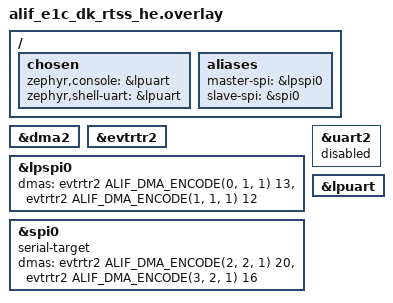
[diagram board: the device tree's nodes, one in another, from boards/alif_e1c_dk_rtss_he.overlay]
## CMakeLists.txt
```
# Copyright (C) 2024 Alif Semiconductor - All Rights Reserved.
# Use, distribution and modification of this code is permitted under the
# terms stated in the Alif Semiconductor Software License Agreement
#
# You should have received a copy of the Alif Semiconductor Software
# License Agreement with this file. If not, please write to:
# contact@alifsemi.com, or visit: https://alifsemi.com/license

cmake_minimum_required(VERSION 3.20.0)
find_package(Zephyr REQUIRED HINTS $ENV{ZEPHYR_BASE})
project(spi_dw)

FILE(GLOB app_sources src/*.c)
target_sources(app PRIVATE ${app_sources})
```

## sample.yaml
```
sample:
  name: SPI Designware Driver Sample
tests:
  sample.drivers.spi.dw:
    tags: drivers spi gpio
    platform_allow: ensemble
    depends_on: gpio
```

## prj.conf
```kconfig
# Copyright (C) 2024 Alif Semiconductor - All Rights Reserved.
# Use, distribution and modification of this code is permitted under the
# terms stated in the Alif Semiconductor Software License Agreement
#
# You should have received a copy of the Alif Semiconductor Software
# License Agreement with this file. If not, please write to:
# contact@alifsemi.com, or visit: https://alifsemi.com/license

CONFIG_STDOUT_CONSOLE=y
CONFIG_SPI=y
CONFIG_SPI_DW=y
CONFIG_SPI_SLAVE=y
CONFIG_SPI_LOG_LEVEL_INF=n
CONFIG_SPI_LOG_LEVEL_DBG=n
CONFIG_LOG=n
CONFIG_DMA=y
CONFIG_DMA_PL330=y
CONFIG_SPI_DW_USE_DMA=y
CONFIG_PRINTK=y
CONFIG_DMA_LOG_LEVEL_INF=n
```

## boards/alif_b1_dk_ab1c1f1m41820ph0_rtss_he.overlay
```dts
/* Copyright (C) 2025 Alif Semiconductor - All Rights Reserved.
 * Use, distribution and modification of this code is permitted under the
 * terms stated in the Alif Semiconductor Software License Agreement
 *
 * You should have received a copy of the Alif Semiconductor Software
 * License Agreement with this file. If not, please write to:
 * contact@alifsemi.com, or visit: https://alifsemi.com/license
 *
 */


/* For SPI master SS(slave select) as:
 * - H/W controlled (default):
 *   - use SS pinmux as H/W
 *     - example for SPI1 as master "PIN_P14_7__SPI1_SS0_C"
 *  "OR"
 * - S/W controlled using gpio:
 *   - use SS pinmux as gpio
 *     - example for SPI1 as master "PIN_P14_7__GPIO"
 *   - define cs-gpios property
 *     - example for SPI1 as master
 *        cs-gpios = <&gpio14 7 GPIO_ACTIVE_LOW>;
 */

 /* default SPI master SS(slave select) is H/W controlled,
  * enable this to use as S/W controlled using gpio.
  */
#define SPI_MASTER_SS_SW_CONTROLLED_GPIO   0

/* setting LPSPI0 as master and SPI1 instance as slave. */
/ {
	aliases {
		master-spi = &lpspi0;
		slave-spi = &spi1;
	};
};

&dma2 {
	status = "okay";
};

&lpspi0 { /* lpspi0 */
	status = "okay";

	dmas = <&dma2 0 13>, <&dma2 1 12>;
	dma-names = "txdma", "rxdma";

#if SPI_MASTER_SS_SW_CONTROLLED_GPIO
	cs-gpios = <&gpio2 0 GPIO_ACTIVE_LOW>;
	/* as we are testing Loopback on the same board,
	 * make sure master interrupt priority is
	 * higher than slave interrupt priority.
	 */
	interrupts = <46 0>;
#endif /* SPI_MASTER_SS_SW_CONTROLLED_GPIO */
};

#if SPI_MASTER_SS_SW_CONTROLLED_GPIO
/* use SPI master SS pinmux as gpio. */
&pinctrl_lpspi0 {
	group0 {
		pinmux = < PIN_P1_3__LPSPI_MISO_A >,
			 < PIN_P1_4__LPSPI_MOSI_A >,
			 < PIN_P1_5__LPSPI_SCLK_A >,
			 < PIN_P2_0__GPIO >;
		read-enable = < 0x1 >;
	};
};

&gpio2 {
	status = "okay";
};
#endif /* SPI_MASTER_SS_SW_CONTROLLED_GPIO */

&spi1 { /* spi1 */
	status = "okay";
	serial-target;

	dmas = <&dma2 2 21>, <&dma2 3 17>;
	dma-names = "txdma", "rxdma";

#if SPI_MASTER_SS_SW_CONTROLLED_GPIO
	interrupts = <138 1>;
#endif
};
```

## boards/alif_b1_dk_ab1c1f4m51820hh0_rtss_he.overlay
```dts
/* Copyright (C) 2025 Alif Semiconductor - All Rights Reserved.
 * Use, distribution and modification of this code is permitted under the
 * terms stated in the Alif Semiconductor Software License Agreement
 *
 * You should have received a copy of the Alif Semiconductor Software
 * License Agreement with this file. If not, please write to:
 * contact@alifsemi.com, or visit: https://alifsemi.com/license
 *
 */


/* For SPI master SS(slave select) as:
 * - H/W controlled (default):
 *   - use SS pinmux as H/W
 *     - example for SPI1 as master "PIN_P14_7__SPI1_SS0_C"
 *  "OR"
 * - S/W controlled using gpio:
 *   - use SS pinmux as gpio
 *     - example for SPI1 as master "PIN_P14_7__GPIO"
 *   - define cs-gpios property
 *     - example for SPI1 as master
 *        cs-gpios = <&gpio14 7 GPIO_ACTIVE_LOW>;
 */

 /* default SPI master SS(slave select) is H/W controlled,
  * enable this to use as S/W controlled using gpio.
  */
#define SPI_MASTER_SS_SW_CONTROLLED_GPIO   0

/* Enable to use Event Router driver instead of manual configuration
 * When enabled:
 * - DMA routing goes through event router driver
 * - Manual event router configuration in main.c is disabled
 * When disabled:
 * - Direct DMA approach with manual event router programming
 */
#define USE_EVENT_ROUTER_DRIVER   1

/* setting LPSPI0 as master and SPI1 instance as slave. */
/ {
	aliases {
		master-spi = &lpspi0;
		slave-spi = &spi1;
	};
};

&dma2 {
	status = "okay";
};

#if USE_EVENT_ROUTER_DRIVER
/* Event Router driver approach: route through event router */
#include <zephyr/dt-bindings/dma/alif_dma_event_router.h>

&evtrtr2 {
	status = "okay";
};

&lpspi0 { /* lpspi0 */
	status = "okay";
	/*
	 * Cell 0: ALIF_DMA_ENCODE(channel, dma_group, handshake)
	 *   - channel: Physical DMA channel (0 for TX, 1 for RX)
	 *   - dma_group: Input source selection (2) - selects which peripheral input
	 *   - handshake: Enable hardware handshaking (1 for SPI)
	 * Cell 1: Peripheral request number (13 for TX, 12 for RX)
	 */
	dmas = <&evtrtr2 ALIF_DMA_ENCODE(0, 1, 1) 13>,
	       <&evtrtr2 ALIF_DMA_ENCODE(1, 1, 1) 12>;
	dma-names = "txdma", "rxdma";

#if SPI_MASTER_SS_SW_CONTROLLED_GPIO
	cs-gpios = <&gpio2 0 GPIO_ACTIVE_LOW>;
	/* as we are testing Loopback on the same board,
	 * make sure master interrupt priority is
	 * higher than slave interrupt priority.
	 */
	interrupts = <46 0>;
#endif /* SPI_MASTER_SS_SW_CONTROLLED_GPIO */
};

&spi1 { /* spi1 */
	status = "okay";
	serial-target;
	/*
	 * Cell 0: ALIF_DMA_ENCODE(channel, dma_group, handshake)
	 *   - channel: Physical DMA channel (2 for TX, 3 for RX)
	 *   - dma_group: Input source selection (2) - selects which peripheral input
	 *   - handshake: Enable hardware handshaking (1 for SPI)
	 * Cell 1: Peripheral request number (21 for TX, 17 for RX)
	 */
	dmas = <&evtrtr2 ALIF_DMA_ENCODE(2, 2, 1) 21>,
	       <&evtrtr2 ALIF_DMA_ENCODE(3, 2, 1) 17>;
	dma-names = "txdma", "rxdma";

#if SPI_MASTER_SS_SW_CONTROLLED_GPIO
	interrupts = <138 1>;
#endif
};

#else
/* Direct DMA approach: manual event router configuration in main.c */

&lpspi0 { /* lpspi0 */
	status = "okay";
	/* Direct PL330 DMA specifier format:
	 * Cell 0: PL330 physical channel (0 for TX, 1 for RX)
	 * Cell 1: PL330 peripheral request (13 for TX, 12 for RX)
	 * Note: Event router is manually configured in main.c
	 */
	dmas = <&dma2 0 13>, <&dma2 1 12>;
	dma-names = "txdma", "rxdma";

#if SPI_MASTER_SS_SW_CONTROLLED_GPIO
	cs-gpios = <&gpio2 0 GPIO_ACTIVE_LOW>;
	/* as we are testing Loopback on the same board,
	 * make sure master interrupt priority is
	 * higher than slave interrupt priority.
	 */
	interrupts = <46 0>;
#endif /* SPI_MASTER_SS_SW_CONTROLLED_GPIO */
};

&spi1 { /* spi1 */
	status = "okay";
	serial-target;
	/* Direct PL330 DMA specifier format:
	 * Cell 0: PL330 physical channel (2 for TX, 3 for RX)
	 * Cell 1: PL330 peripheral request (21 for TX, 17 for RX)
	 * Note: Event router is manually configured in main.c
	 */
	dmas = <&dma2 2 21>, <&dma2 3 17>;
	dma-names = "txdma", "rxdma";

#if SPI_MASTER_SS_SW_CONTROLLED_GPIO
	interrupts = <138 1>;
#endif
};

#endif /* USE_EVENT_ROUTER_DRIVER */

#if SPI_MASTER_SS_SW_CONTROLLED_GPIO
/* use SPI master SS pinmux as gpio. */
&pinctrl_lpspi0 {
	group0 {
		pinmux = < PIN_P1_3__LPSPI_MISO_A >,
			 < PIN_P1_4__LPSPI_MOSI_A >,
			 < PIN_P1_5__LPSPI_SCLK_A >,
			 < PIN_P2_0__GPIO >;
		read-enable = < 0x1 >;
	};
};

&gpio2 {
	status = "okay";
};
#endif /* SPI_MASTER_SS_SW_CONTROLLED_GPIO */
```

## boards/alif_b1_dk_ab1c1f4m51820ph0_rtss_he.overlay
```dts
/* Copyright (C) 2025 Alif Semiconductor - All Rights Reserved.
 * Use, distribution and modification of this code is permitted under the
 * terms stated in the Alif Semiconductor Software License Agreement
 *
 * You should have received a copy of the Alif Semiconductor Software
 * License Agreement with this file. If not, please write to:
 * contact@alifsemi.com, or visit: https://alifsemi.com/license
 *
 */


/* For SPI master SS(slave select) as:
 * - H/W controlled (default):
 *   - use SS pinmux as H/W
 *     - example for SPI1 as master "PIN_P14_7__SPI1_SS0_C"
 *  "OR"
 * - S/W controlled using gpio:
 *   - use SS pinmux as gpio
 *     - example for SPI1 as master "PIN_P14_7__GPIO"
 *   - define cs-gpios property
 *     - example for SPI1 as master
 *        cs-gpios = <&gpio14 7 GPIO_ACTIVE_LOW>;
 */

 /* default SPI master SS(slave select) is H/W controlled,
  * enable this to use as S/W controlled using gpio.
  */
#define SPI_MASTER_SS_SW_CONTROLLED_GPIO   0

/* Enable to use Event Router driver instead of manual configuration
 * When enabled:
 * - DMA routing goes through event router driver
 * - Manual event router configuration in main.c is disabled
 * When disabled:
 * - Direct DMA approach with manual event router programming
 */
#define USE_EVENT_ROUTER_DRIVER   1

/* setting LPSPI0 as master and SPI1 instance as slave. */
/ {
	aliases {
		master-spi = &lpspi0;
		slave-spi = &spi1;
	};
};

&dma2 {
	status = "okay";
};

#if USE_EVENT_ROUTER_DRIVER
/* Event Router driver approach: route through event router */
#include <zephyr/dt-bindings/dma/alif_dma_event_router.h>

&evtrtr2 {
	status = "okay";
};

&lpspi0 { /* lpspi0 */
	status = "okay";
	/*
	 * Cell 0: ALIF_DMA_ENCODE(channel, dma_group, handshake)
	 *   - channel: Physical DMA channel (0 for TX, 1 for RX)
	 *   - dma_group: Input source selection (2) - selects which peripheral input
	 *   - handshake: Enable hardware handshaking (1 for SPI)
	 * Cell 1: Peripheral request number (13 for TX, 12 for RX)
	 */
	dmas = <&evtrtr2 ALIF_DMA_ENCODE(0, 1, 1) 13>,
	       <&evtrtr2 ALIF_DMA_ENCODE(1, 1, 1) 12>;
	dma-names = "txdma", "rxdma";

#if SPI_MASTER_SS_SW_CONTROLLED_GPIO
	cs-gpios = <&gpio2 0 GPIO_ACTIVE_LOW>;
	/* as we are testing Loopback on the same board,
	 * make sure master interrupt priority is
	 * higher than slave interrupt priority.
	 */
	interrupts = <46 0>;
#endif /* SPI_MASTER_SS_SW_CONTROLLED_GPIO */
};

&spi1 { /* spi1 */
	status = "okay";
	serial-target;
	/*
	 * Cell 0: ALIF_DMA_ENCODE(channel, dma_group, handshake)
	 *   - channel: Physical DMA channel (2 for TX, 3 for RX)
	 *   - dma_group: Input source selection (2) - selects which peripheral input
	 *   - handshake: Enable hardware handshaking (1 for SPI)
	 * Cell 1: Peripheral request number (21 for TX, 17 for RX)
	 */
	dmas = <&evtrtr2 ALIF_DMA_ENCODE(2, 2, 1) 21>,
	       <&evtrtr2 ALIF_DMA_ENCODE(3, 2, 1) 17>;
	dma-names = "txdma", "rxdma";

#if SPI_MASTER_SS_SW_CONTROLLED_GPIO
	interrupts = <138 1>;
#endif
};

#else
/* Direct DMA approach: manual event router configuration in main.c */

&lpspi0 { /* lpspi0 */
	status = "okay";
	/* Direct PL330 DMA specifier format:
	 * Cell 0: PL330 physical channel (0 for TX, 1 for RX)
	 * Cell 1: PL330 peripheral request (13 for TX, 12 for RX)
	 * Note: Event router is manually configured in main.c
	 */
	dmas = <&dma2 0 13>, <&dma2 1 12>;
	dma-names = "txdma", "rxdma";

#if SPI_MASTER_SS_SW_CONTROLLED_GPIO
	cs-gpios = <&gpio2 0 GPIO_ACTIVE_LOW>;
	/* as we are testing Loopback on the same board,
	 * make sure master interrupt priority is
	 * higher than slave interrupt priority.
	 */
	interrupts = <46 0>;
#endif /* SPI_MASTER_SS_SW_CONTROLLED_GPIO */
};

&spi1 { /* spi1 */
	status = "okay";
	serial-target;
	/* Direct PL330 DMA specifier format:
	 * Cell 0: PL330 physical channel (2 for TX, 3 for RX)
	 * Cell 1: PL330 peripheral request (21 for TX, 17 for RX)
	 * Note: Event router is manually configured in main.c
	 */
	dmas = <&dma2 2 21>, <&dma2 3 17>;
	dma-names = "txdma", "rxdma";

#if SPI_MASTER_SS_SW_CONTROLLED_GPIO
	interrupts = <138 1>;
#endif
};

#endif /* USE_EVENT_ROUTER_DRIVER */

#if SPI_MASTER_SS_SW_CONTROLLED_GPIO
/* use SPI master SS pinmux as gpio. */
&pinctrl_lpspi0 {
	group0 {
		pinmux = < PIN_P1_3__LPSPI_MISO_A >,
			 < PIN_P1_4__LPSPI_MOSI_A >,
			 < PIN_P1_5__LPSPI_SCLK_A >,
			 < PIN_P2_0__GPIO >;
		read-enable = < 0x1 >;
	};
};

&gpio2 {
	status = "okay";
};
#endif /* SPI_MASTER_SS_SW_CONTROLLED_GPIO */
```

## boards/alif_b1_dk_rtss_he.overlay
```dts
/* Copyright (C) 2025 Alif Semiconductor - All Rights Reserved.
* Use, distribution and modification of this code is permitted under the
* terms stated in the Alif Semiconductor Software License Agreement
*
* You should have received a copy of the Alif Semiconductor Software
* License Agreement with this file. If not, please write to:
* contact@alifsemi.com, or visit: https://alifsemi.com/license
*
*/

/* setting LPSPI0 as master and SPI0 instance as slave.
 *
 */

/* For SPI master SS(slave select) as:
 * - H/W controlled (default):
 *   - use SS pinmux as H/W
 *     - example for SPI1 as master "PIN_P14_7__SPI1_SS0_C"
 *  "OR"
 * - S/W controlled using gpio:
 *   - use SS pinmux as gpio
 *     - example for SPI1 as master "PIN_P14_7__GPIO"
 *   - define cs-gpios property
 *     - example for SPI1 as master
 *        cs-gpios = <&gpio14 7 GPIO_ACTIVE_LOW>;
 */

 /* default SPI master SS(slave select) is H/W controlled,
  * enable this to use as S/W controlled using gpio.
  */
#define SPI_MASTER_SS_SW_CONTROLLED_GPIO   0

/ {

	chosen {
		zephyr,console = &lpuart;
		zephyr,shell-uart = &lpuart;
	};
	aliases {
		master-spi = &lpspi0;
		slave-spi = &spi0;
	};
};

&dma2 {
	status = "okay";
};

&lpspi0 {
	status = "okay";

	dmas = <&dma2 0 13>, <&dma2 1 12>;
	dma-names = "txdma", "rxdma";

#if SPI_MASTER_SS_SW_CONTROLLED_GPIO
	cs-gpios = <&gpio2 0 GPIO_ACTIVE_LOW>;
	/* as we are testing Loopback on the same board,
	 * make sure master interrupt priority is
	 * higher than slave interrupt priority.
	 */
	interrupts = <46 0>;
#endif /* SPI_MASTER_SS_SW_CONTROLLED_GPIO */
};

#if SPI_MASTER_SS_SW_CONTROLLED_GPIO
/* use SPI master SS pinmux as gpio. */
&pinctrl_lpspi0 {
	group0 {
		pinmux = < PIN_P1_3__LPSPI_MISO_A >,
			 < PIN_P1_4__LPSPI_MOSI_A >,
			 < PIN_P1_5__LPSPI_SCLK_A >,
			 < PIN_P2_0__GPIO >;
		read-enable = < 0x1 >;
	};
};

&gpio2 {
	status = "okay";
};
#endif /* SPI_MASTER_SS_SW_CONTROLLED_GPIO */

&spi0 {
	status = "okay";
	serial-target;

	dmas = <&dma2 2 20>, <&dma2 3 16>;
	dma-names = "txdma", "rxdma";

#if SPI_MASTER_SS_SW_CONTROLLED_GPIO
	interrupts = <137 1>;
#endif
};

&uart2 {
	status = "disabled";
};

&lpuart {
	status = "okay";
};
```

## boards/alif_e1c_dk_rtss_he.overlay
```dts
/* Copyright (C) 2025 Alif Semiconductor - All Rights Reserved.
* Use, distribution and modification of this code is permitted under the
* terms stated in the Alif Semiconductor Software License Agreement
*
* You should have received a copy of the Alif Semiconductor Software
* License Agreement with this file. If not, please write to:
* contact@alifsemi.com, or visit: https://alifsemi.com/license
*
*/

/* setting LPSPI0 as master and SPI0 instance as slave.
*
*/

/* For SPI master SS(slave select) as:
 * - H/W controlled (default):
 *   - use SS pinmux as H/W
 *     - example for SPI1 as master "PIN_P14_7__SPI1_SS0_C"
 *  "OR"
 * - S/W controlled using gpio:
 *   - use SS pinmux as gpio
 *     - example for SPI1 as master "PIN_P14_7__GPIO"
 *   - define cs-gpios property
 *     - example for SPI1 as master
 *        cs-gpios = <&gpio14 7 GPIO_ACTIVE_LOW>;
 */

 /* default SPI master SS(slave select) is H/W controlled,
  * enable this to use as S/W controlled using gpio.
  */
#define SPI_MASTER_SS_SW_CONTROLLED_GPIO   0

/* Enable to use Event Router driver instead of manual configuration
 * When enabled:
 * - DMA routing goes through event router driver
 * - Manual event router configuration in main.c is disabled
 * When disabled:
 * - Direct DMA approach with manual event router programming
 */
#define USE_EVENT_ROUTER_DRIVER   1

/ {

	chosen {
		zephyr,console = &lpuart;
		zephyr,shell-uart = &lpuart;
	};
	aliases {
		master-spi = &lpspi0;
		slave-spi = &spi0;
	};
};

&dma2 {
	status = "okay";
};

#if USE_EVENT_ROUTER_DRIVER
/* Event Router driver approach: route through event router */
#include <zephyr/dt-bindings/dma/alif_dma_event_router.h>

&evtrtr2 {
	status = "okay";
};

&lpspi0 {
	status = "okay";
	/*
	 * Cell 0: ALIF_DMA_ENCODE(channel, dma_group, handshake)
	 *   - channel: Physical DMA channel (0 for TX, 1 for RX)
	 *   - dma_group: Input source selection (2) - selects which peripheral input
	 *   - handshake: Enable hardware handshaking (1 for SPI)
	 * Cell 1: Peripheral request number (13 for TX, 12 for RX)
	 */
	dmas = <&evtrtr2 ALIF_DMA_ENCODE(0, 1, 1) 13>,
	       <&evtrtr2 ALIF_DMA_ENCODE(1, 1, 1) 12>;
	dma-names = "txdma", "rxdma";

#if SPI_MASTER_SS_SW_CONTROLLED_GPIO
	cs-gpios = <&gpio2 0 GPIO_ACTIVE_LOW>;
	/* as we are testing Loopback on the same board,
	 * make sure master interrupt priority is
	 * higher than slave interrupt priority.
	 */
	interrupts = <46 0>;
#endif /* SPI_MASTER_SS_SW_CONTROLLED_GPIO */
};

&spi0 {
	status = "okay";
	serial-target;
	/*
	 * Cell 0: ALIF_DMA_ENCODE(channel, dma_group, handshake)
	 *   - channel: Physical DMA channel (2 for TX, 3 for RX)
	 *   - dma_group: Input source selection (2) - selects which peripheral input
	 *   - handshake: Enable hardware handshaking (1 for SPI)
	 * Cell 1: Peripheral request number (20 for TX, 16 for RX)
	 */
	dmas = <&evtrtr2 ALIF_DMA_ENCODE(2, 2, 1) 20>,
	       <&evtrtr2 ALIF_DMA_ENCODE(3, 2, 1) 16>;
	dma-names = "txdma", "rxdma";

#if SPI_MASTER_SS_SW_CONTROLLED_GPIO
	interrupts = <137 1>;
#endif
};

#else
/* Direct DMA approach: manual event router configuration in main.c */

&lpspi0 {
	status = "okay";
	/* Direct PL330 DMA specifier format:
	 * Cell 0: PL330 physical channel (0 for TX, 1 for RX)
	 * Cell 1: PL330 peripheral request (13 for TX, 12 for RX)
	 * Note: Event router is manually configured in main.c
	 */
	dmas = <&dma2 0 13>, <&dma2 1 12>;
	dma-names = "txdma", "rxdma";

#if SPI_MASTER_SS_SW_CONTROLLED_GPIO
	cs-gpios = <&gpio2 0 GPIO_ACTIVE_LOW>;
	/* as we are testing Loopback on the same board,
	 * make sure master interrupt priority is
	 * higher than slave interrupt priority.
	 */
	interrupts = <46 0>;
#endif /* SPI_MASTER_SS_SW_CONTROLLED_GPIO */
};

&spi0 {
	status = "okay";
	serial-target;
	/* Direct PL330 DMA specifier format:
	 * Cell 0: PL330 physical channel (2 for TX, 3 for RX)
	 * Cell 1: PL330 peripheral request (20 for TX, 16 for RX)
	 * Note: Event router is manually configured in main.c
	 */
	dmas = <&dma2 2 20>, <&dma2 3 16>;
	dma-names = "txdma", "rxdma";

#if SPI_MASTER_SS_SW_CONTROLLED_GPIO
	interrupts = <137 1>;
#endif
};

#endif /* USE_EVENT_ROUTER_DRIVER */

#if SPI_MASTER_SS_SW_CONTROLLED_GPIO
/* use SPI master SS pinmux as gpio. */
&pinctrl_lpspi0 {
	group0 {
		pinmux = < PIN_P1_3__LPSPI_MISO_A >,
			 < PIN_P1_4__LPSPI_MOSI_A >,
			 < PIN_P1_5__LPSPI_SCLK_A >,
			 < PIN_P2_0__GPIO >;
		read-enable = < 0x1 >;
	};
};

&gpio2 {
	status = "okay";
};
#endif /* SPI_MASTER_SS_SW_CONTROLLED_GPIO */

&uart2 {
	status = "disabled";
};

&lpuart {
	status = "okay";
};
```

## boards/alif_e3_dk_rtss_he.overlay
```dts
/* Copyright (C) 2025 Alif Semiconductor - All Rights Reserved.
 * Use, distribution and modification of this code is permitted under the
 * terms stated in the Alif Semiconductor Software License Agreement
 *
 * You should have received a copy of the Alif Semiconductor Software
 * License Agreement with this file. If not, please write to:
 * contact@alifsemi.com, or visit: https://alifsemi.com/license
 *
 */

/* setting SPI4 as master and SPI0 instance as slave.
 *
 */

/* For SPI master SS(slave select) as:
 * - H/W controlled (default):
 *   - use SS pinmux as H/W
 *     - example for SPI4 as master "PIN_P7_7__LPSPI_SS_A"
 *  "OR"
 * - S/W controlled using gpio:
 *   - use SS pinmux as gpio
 *     - example for SPI4 as master "PIN_P7_7__GPIO"
 *   - define cs-gpios property
 *     - example for SPI4 as master
 *        cs-gpios = <&gpio7 7 GPIO_ACTIVE_LOW>;
 */

/* default SPI master SS(slave select) is H/W controlled,
 * enable this to use as S/W controlled using gpio.
 */
#define SPI_MASTER_SS_SW_CONTROLLED_GPIO   0

/* Enable to use Event Router driver instead of manual configuration
 * When enabled:
 * - DMA routing goes through event router driver
 * - Manual event router configuration in main.c is disabled
 * When disabled:
 * - Direct DMA approach with manual event router programming
 */
#define USE_EVENT_ROUTER_DRIVER   1

/ {
	aliases {
		master-spi = &spi4;
		slave-spi = &spi0;
	};
};

&dma2 {
	status = "okay";
};

&dma0 {
	status = "okay";
};

#if USE_EVENT_ROUTER_DRIVER
/* Event Router driver approach: route through event router */
#include <zephyr/dt-bindings/dma/alif_dma_event_router.h>

&evtrtr2 {
	status = "okay";
};

&evtrtr0 {
	status = "okay";
};

&spi4 {
	status = "okay";
	/*
	 * Cell 0: ALIF_DMA_ENCODE(channel, dma_group, handshake)
	 *   - channel: Physical DMA channel (0 for TX, 1 for RX)
	 *   - dma_group: Input source selection (0) - selects which peripheral input
	 *   - handshake: Enable hardware handshaking (1 for SPI)
	 * Cell 1: Peripheral request number (13 for TX, 12 for RX)
	 */
	dmas = <&evtrtr2 ALIF_DMA_ENCODE(0, 0, 1) 13>,
	       <&evtrtr2 ALIF_DMA_ENCODE(1, 0, 1) 12>;
/* If user wants to use dma0 for master spi(spi4) with event router:
 * dmas = <&evtrtr0 ALIF_DMA_ENCODE(0, 2, 1) 25>,
 *        <&evtrtr0 ALIF_DMA_ENCODE(1, 2, 1) 24>;
 */
	dma-names = "txdma", "rxdma";

#if SPI_MASTER_SS_SW_CONTROLLED_GPIO
	cs-gpios = <&gpio7 7 GPIO_ACTIVE_LOW>;
	/* as we are testing Loopback on the same board,
	 * make sure master interrupt priority is
	 * higher than slave interrupt priority.
	 */
	interrupts = <46 0>;
#endif /* SPI_MASTER_SS_SW_CONTROLLED_GPIO */
};

&spi0 {
	status = "okay";
	serial-target;
	/*
	 * Cell 0: ALIF_DMA_ENCODE(channel, dma_group, handshake)
	 *   - channel: Physical DMA channel (2 for TX, 3 for RX)
	 *   - dma_group: Input source selection (2) - selects which peripheral input
	 *   - handshake: Enable hardware handshaking (1 for SPI)
	 * Cell 1: Peripheral request number (20 for TX, 16 for RX)
	 */
	dmas = <&evtrtr0 ALIF_DMA_ENCODE(2, 2, 1) 20>,
	       <&evtrtr0 ALIF_DMA_ENCODE(3, 2, 1) 16>;
	dma-names = "txdma", "rxdma";

#if SPI_MASTER_SS_SW_CONTROLLED_GPIO
	interrupts = <137 1>;
#endif
};

#else
/* Direct DMA approach: manual event router configuration in main.c */

&spi4 {
	status = "okay";
	/* Direct PL330 DMA specifier format:
	 * Cell 0: PL330 physical channel (0 for TX, 1 for RX)
	 * Cell 1: PL330 peripheral request (13 for TX, 12 for RX)
	 * Note: Event router is manually configured in main.c
	 */
	dmas = <&dma2 0 13>, <&dma2 1 12>;
/* If user want to use dma0 for master spi(spi4),
 * add below dmas property:
 * dmas = <&dma0 0 25>, <&dma0 1 24>;
 */
	dma-names = "txdma", "rxdma";

#if SPI_MASTER_SS_SW_CONTROLLED_GPIO
	cs-gpios = <&gpio7 7 GPIO_ACTIVE_LOW>;
	/* as we are testing Loopback on the same board,
	 * make sure master interrupt priority is
	 * higher than slave interrupt priority.
	 */
	interrupts = <46 0>;
#endif /* SPI_MASTER_SS_SW_CONTROLLED_GPIO */
};

&spi0 {
	status = "okay";
	serial-target;
	/* Direct PL330:
	 * Cell 0: PL330 physical channel (2 for TX, 3 for RX)
	 * Cell 1: PL330 peripheral request (20 for TX, 16 for RX)
	 * Note: Event router is manually configured in main.c
	 */
	dmas = <&dma0 2 20>, <&dma0 3 16>;
	dma-names = "txdma", "rxdma";

#if SPI_MASTER_SS_SW_CONTROLLED_GPIO
	interrupts = <137 1>;
#endif
};

#endif /* USE_EVENT_ROUTER_DRIVER */

#if SPI_MASTER_SS_SW_CONTROLLED_GPIO
/* use SPI master SS pinmux as gpio. */
&pinctrl_lpspi {
	group0 {
		pinmux = < PIN_P7_4__LPSPI_MISO_A >,
			 < PIN_P7_5__LPSPI_MOSI_A >,
			 < PIN_P7_6__LPSPI_SCLK_A >,
			 < PIN_P7_7__GPIO >;
		read-enable = < 0x1 >;
	};
};

&gpio7 {
	status = "okay";
};
#endif /* SPI_MASTER_SS_SW_CONTROLLED_GPIO */
```

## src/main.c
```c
/* Copyright (C) 2025 Alif Semiconductor - All Rights Reserved.
 * Use, distribution and modification of this code is permitted under the
 * terms stated in the Alif Semiconductor Software License Agreement
 *
 * You should have received a copy of the Alif Semiconductor Software
 * License Agreement with this file. If not, please write to:
 * contact@alifsemi.com, or visit: https://alifsemi.com/license
 *
 */

#include <zephyr/logging/log.h>
LOG_MODULE_REGISTER(app, LOG_LEVEL_INF);

#include <zephyr/kernel.h>
#include <zephyr/device.h>
#include <zephyr/devicetree.h>
#include <string.h>
#include <zephyr/drivers/spi.h>
#include <zephyr/dt-bindings/dma/alif_dma_event_router.h>
#include <soc_common.h>

#define Mhz		1000000
#define Khz		1000

/* master_spi and slave_spi aliases are defined in
 * overlay files to use different SPI instance if needed.
 */

#define SPIDW_NODE	DT_ALIAS(master_spi)

#define S_SPIDW_NODE	DT_ALIAS(slave_spi)

/* size of stack area used by each thread */
#define STACKSIZE 1024

/* default SPI master SS(slave select) is H/W controlled,
 * enable this to use as S/W controlled using gpio.
 */
#define SPI_MASTER_SS_SW_CONTROLLED_GPIO   0


/* scheduling priority used by each thread,
 * as we are testing Loopback on the same board,
 * make sure master priority is higher than slave priority.
 */
#define MASTER_PRIORITY 6
#define SLAVE_PRIORITY  7

/* delay between greetings (in ms) */
#define SLEEPTIME 1000

K_THREAD_STACK_DEFINE(MasterT_stack, STACKSIZE);
static struct k_thread MasterT_data;

K_THREAD_STACK_DEFINE(SlaveT_stack, STACKSIZE);
static struct k_thread SlaveT_data;

/* Master and Slave buffer size */
#define BUFF_SIZE  200

/* Master and Slave buffer word size */
#define SPI_WORD_SIZE 8

/* Master and Slave buffer frequency */
#define SPI_FREQUENCY (1 * Mhz)

/* Master and Slave buffer transfers */
#define SPI_NUM_TRANSFERS  10

#define SPI_BUF_BYTES ROUND_UP(BUFF_SIZE * sizeof(uint32_t), CONFIG_DCACHE_LINE_SIZE)
#define SPI_BUF_WORDS (SPI_BUF_BYTES / sizeof(uint32_t))

/* Master and Slave buffers */
static __aligned(CONFIG_DCACHE_LINE_SIZE) uint32_t master_txdata[SPI_BUF_WORDS];
static __aligned(CONFIG_DCACHE_LINE_SIZE) uint32_t master_rxdata[SPI_BUF_WORDS];
static __aligned(CONFIG_DCACHE_LINE_SIZE) uint32_t slave_txdata[SPI_BUF_WORDS];
static __aligned(CONFIG_DCACHE_LINE_SIZE) uint32_t slave_rxdata[SPI_BUF_WORDS];

/*
 * Send/Receive data through slave spi
 */
int slave_spi_transceive(const struct device *dev)
{
	struct spi_config cnfg;
	int ret;

	cnfg.frequency = SPI_FREQUENCY;
	cnfg.operation = SPI_OP_MODE_SLAVE | SPI_WORD_SET(SPI_WORD_SIZE);
	cnfg.slave = 0;

	int length = (BUFF_SIZE) * sizeof(slave_rxdata[0]);

	struct spi_buf rx_buf = {
		.buf = slave_rxdata,
		.len = length
	};
	struct spi_buf_set rx_bufset = {
		.buffers = &rx_buf,
		.count = 1
	};
	struct spi_buf tx_buf = {
		.buf = slave_txdata,
		.len = length
	};
	struct spi_buf_set tx_bufset = {
		.buffers = &tx_buf,
		.count = 1
	};

	ret = spi_transceive(dev, &cnfg, &tx_bufset, &rx_bufset);
	if (ret < 0) {
		printk("ERROR: Slave SPI Transceive: %d\n", ret);
	}

	printk("slave wrote: %08x %08x %08x %08x %08x\n",
		slave_txdata[0], slave_txdata[1], slave_txdata[2],
		slave_txdata[3], slave_txdata[4]);

	printk("slave read: %08x %08x %08x %08x %08x\n",
		slave_rxdata[0], slave_rxdata[1], slave_rxdata[2],
		slave_rxdata[3], slave_rxdata[4]);

	ret = memcmp(master_txdata, slave_rxdata, length);
	if (ret) {
		printk("ERROR: SPI Master TX & Slave RX DATA NOT MATCHING: %d\n", ret);
	} else {
		printk("SUCCESS: SPI Master TX & Slave RX DATA IS MATCHING: %d\n", ret);
	}

	return ret;
}

/*
 * Send/Receive data through master spi
 */
int master_spi_transceive(const struct device *dev,
				 struct spi_cs_control *cs)
{
	struct spi_config cnfg;
	int ret;

	cnfg.frequency = SPI_FREQUENCY;
	cnfg.operation = SPI_OP_MODE_MASTER | SPI_WORD_SET(SPI_WORD_SIZE);
	cnfg.slave = 0;
	cnfg.cs = *cs;

	int length = (BUFF_SIZE) * sizeof(master_txdata[0]);

	struct spi_buf tx_buf = {
		.buf = master_txdata,
		.len = length
	};

	struct spi_buf_set tx_bufset = {
		.buffers = &tx_buf,
		.count = 1
	};

	struct spi_buf rx_buf = {
		.buf = master_rxdata,
		.len = length
	};
	struct spi_buf_set rx_bufset = {
		.buffers = &rx_buf,
		.count = 1
	};

	ret = spi_transceive(dev, &cnfg, &tx_bufset, &rx_bufset);
	if (ret) {
		printk("ERROR: SPI=%p transceive: %d\n", dev, ret);
	}
	printk("Master wrote: %08x %08x %08x %08x %08x\n",
		master_txdata[0], master_txdata[1], master_txdata[2],
		master_txdata[3], master_txdata[4]);
	printk("Master receive: %08x %08x %08x %08x %08x\n",
		master_rxdata[0], master_rxdata[1], master_rxdata[2],
		master_rxdata[3], master_rxdata[4]);

	ret = memcmp(master_rxdata, slave_txdata, length);
	if (ret) {
		printk("ERROR: SPI Master RX & Slave TX DATA NOT MATCHING: %d\n", ret);
	} else {
		printk("SUCCESS: SPI Master RX & Slave TX DATA IS MATCHING: %d\n", ret);
	}

	return ret;
}

static void master_spi(void *p1, void *p2, void *p3)
{
	const struct device *const dev = DEVICE_DT_GET(SPIDW_NODE);
	uint32_t iterations = SPI_NUM_TRANSFERS;
	int ret;

	ARG_UNUSED(p1);
	ARG_UNUSED(p2);
	ARG_UNUSED(p3);

	if (!device_is_ready(dev)) {
		printk("%s: Master device not ready.\n", dev->name);
		return;
	}

#if SPI_MASTER_SS_SW_CONTROLLED_GPIO /* SPI master SS as S/W controlled using gpio */
	struct spi_cs_control cs_ctrl = (struct spi_cs_control){
		.gpio  = GPIO_DT_SPEC_GET(SPIDW_NODE, cs_gpios),
		.delay = 100u, /* k_busy_wait(uint32_t usec_to_wait) */
	};
#else /* SPI master SS as H/W controlled */
	struct spi_cs_control cs_ctrl = {0};
#endif /* SPI_MASTER_SS_SW_CONTROLLED_GPIO */

	while (iterations) {
		printk("Master Transceive Iter= %d\n", iterations);
		ret = master_spi_transceive(dev, &cs_ctrl);
		k_msleep(SLEEPTIME);
		if (ret < 0) {
			printk("Stopping the Master Thread due to error\n");
			return;
		}
		iterations--;
	}
	printk("Master Transfer Successfully Completed\n");
}

static void slave_spi(void *p1, void *p2, void *p3)
{
	const struct device *const slave_dev = DEVICE_DT_GET(S_SPIDW_NODE);
	uint32_t iterations = SPI_NUM_TRANSFERS;
	int ret;

	ARG_UNUSED(p1);
	ARG_UNUSED(p2);
	ARG_UNUSED(p3);

	if (!device_is_ready(slave_dev)) {
		printk("%s: Slave device not ready\n", slave_dev->name);
		return;
	}

	while (iterations) {
		printk("Slave Transceive Iter= %d\n", iterations);
		ret = slave_spi_transceive(slave_dev);
		if (ret < 0) {
			printk("Stopping the Slave Thread due to error\n");
			return;
		}
		iterations--;
	}
	printk("Slave Transfer Successfully Completed\n");
}

static void prepare_data(uint32_t *data, uint16_t def_mask)
{
	for (uint32_t cnt = 0; cnt < BUFF_SIZE; cnt++) {
		data[cnt] = (def_mask << 16) | cnt;
	}
}

int main(void)
{

	prepare_data(master_txdata, 0xA5A5);
	prepare_data(slave_txdata, 0x5A5A);

	k_tid_t tids = k_thread_create(&SlaveT_data, SlaveT_stack, STACKSIZE,
			&slave_spi, NULL, NULL, NULL,
			SLAVE_PRIORITY, 0, K_NO_WAIT);
	if (tids == NULL) {
		printk("Error creating Slave Thread\n");
	}

	/* as we are testing Loopback on the same board,
	 * make sure slave is ready before master starts.
	 */
	k_msleep(100);
	k_tid_t tidm = k_thread_create(&MasterT_data, MasterT_stack, STACKSIZE,
			&master_spi, NULL, NULL, NULL,
			MASTER_PRIORITY, 0, K_NO_WAIT);
	if (tidm == NULL) {
		printk("Error creating Master Thread\n");
	}

	k_thread_start(&SlaveT_data);
	k_thread_start(&MasterT_data);

	return 0;
}
```
